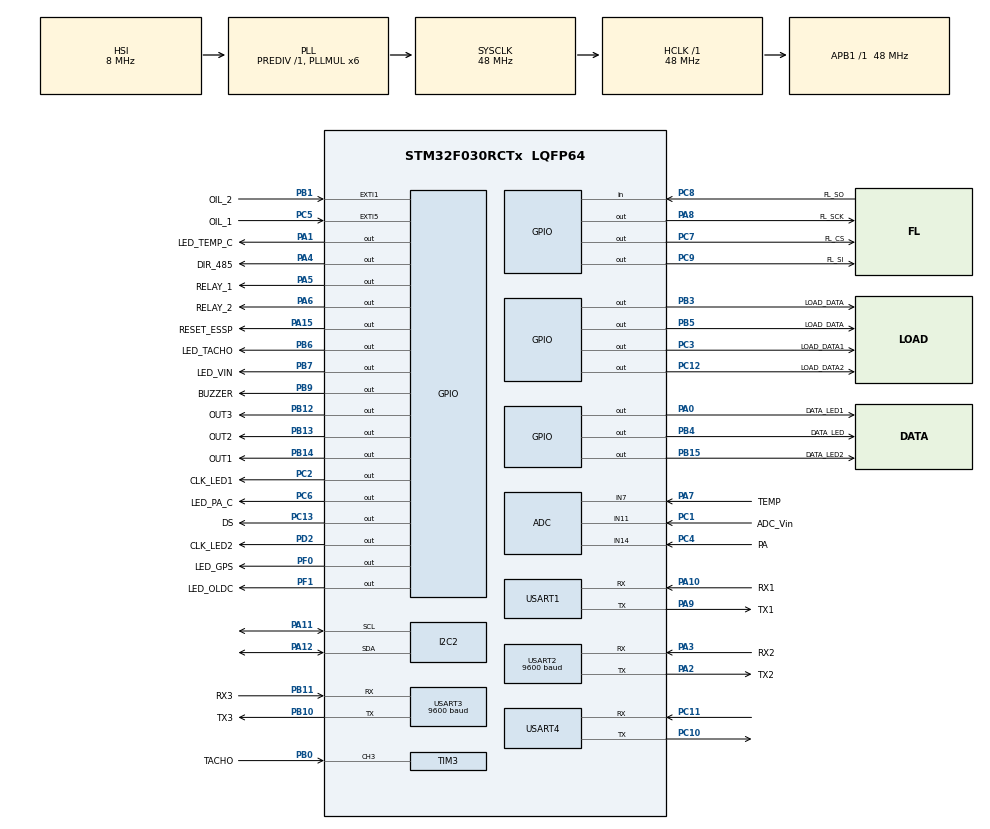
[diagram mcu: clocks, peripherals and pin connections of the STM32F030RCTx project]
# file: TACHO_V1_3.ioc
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I2C2.Timing=0x20303E5D
Mcu.Family=STM32F0
Mcu.Name=STM32F030RCTx
Mcu.Package=LQFP64
NVIC.ADC1_IRQn=true\:2\:0\:true\:false\:true\:true\:true\:true
NVIC.EXTI0_1_IRQn=true\:0\:0\:false\:false\:true\:true\:true\:true
NVIC.EXTI4_15_IRQn=true\:0\:0\:false\:false\:true\:true\:true\:true
NVIC.I2C2_IRQn=true\:2\:0\:true\:false\:true\:true\:true\:true
NVIC.TIM14_IRQn=true\:3\:0\:true\:false\:true\:true\:true\:true
NVIC.TIM1_BRK_UP_TRG_COM_IRQn=true\:3\:0\:true\:false\:true\:true\:true\:true
NVIC.TIM1_CC_IRQn=true\:3\:0\:true\:false\:true\:true\:true\:true
NVIC.TIM3_IRQn=true\:1\:0\:true\:false\:true\:true\:true\:true
NVIC.USART1_IRQn=true\:2\:0\:true\:false\:true\:true\:true\:true
NVIC.USART2_IRQn=true\:2\:0\:true\:false\:true\:true\:true\:true
NVIC.USART3_6_IRQn=true\:2\:0\:true\:false\:true\:true\:true\:true
PA0.GPIO_Label=DATA_LED1
PA0.Signal=GPIO_Output
PA1.GPIO_Label=LED_TEMP_C
PA1.Signal=GPIO_Output
PA10.GPIO_Label=RX1
PA10.Mode=Asynchronous
PA10.Signal=USART1_RX
PA11.Mode=I2C
PA11.Signal=I2C2_SCL
PA12.Mode=I2C
PA12.Signal=I2C2_SDA
PA13.Mode=Serial_Wire
PA13.Signal=SYS_SWDIO
PA14.Mode=Serial_Wire
PA14.Signal=SYS_SWCLK
PA15.GPIO_Label=RESET_ESSP
PA15.Signal=GPIO_Output
PA2.GPIO_Label=TX2
PA2.Mode=Asynchronous
PA2.Signal=USART2_TX
PA3.GPIO_Label=RX2
PA3.Mode=Asynchronous
PA3.Signal=USART2_RX
PA4.GPIO_Label=DIR_485
PA4.Signal=GPIO_Output
PA5.GPIO_Label=RELAY_1
PA5.Signal=GPIO_Output
PA6.GPIO_Label=RELAY_2
PA6.Signal=GPIO_Output
PA7.GPIO_Label=TEMP
PA7.Mode=IN7
PA7.Signal=ADC_IN7
PA8.GPIO_Label=FL_SCK
PA8.Signal=GPIO_Output
PA9.GPIO_Label=TX1
PA9.Mode=Asynchronous
PA9.Signal=USART1_TX
PB0.GPIO_Label=TACHO
PB0.Signal=S_TIM3_CH3
PB1.GPIO_Label=OIL_2
PB1.Signal=GPXTI1
PB10.GPIO_Label=TX3
PB10.Mode=Asynchronous
PB10.Signal=USART3_TX
PB11.GPIO_Label=RX3
PB11.Mode=Asynchronous
PB11.Signal=USART3_RX
PB12.GPIO_Label=OUT3
PB12.Signal=GPIO_Output
PB13.GPIO_Label=OUT2
PB13.Signal=GPIO_Output
PB14.GPIO_Label=OUT1
PB14.Signal=GPIO_Output
PB15.GPIO_Label=DATA_LED2
PB15.Signal=GPIO_Output
PB3.GPIO_Label=LOAD_DATA
PB3.Signal=GPIO_Output
PB4.GPIO_Label=DATA_LED
PB4.Signal=GPIO_Output
PB5.GPIO_Label=LOAD_DATA
PB5.Signal=GPIO_Output
PB6.GPIO_Label=LED_TACHO
PB6.Signal=GPIO_Output
PB7.GPIO_Label=LED_VIN
PB7.Signal=GPIO_Output
PB9.GPIO_Label=BUZZER
PB9.Signal=GPIO_Output
PC1.GPIO_Label=ADC_Vin
PC1.Mode=IN11
PC1.Signal=ADC_IN11
PC10.Mode=Asynchronous
PC10.Signal=USART4_TX
PC11.Mode=Asynchronous
PC11.Signal=USART4_RX
PC12.GPIO_Label=LOAD_DATA2
PC12.Signal=GPIO_Output
PC13.GPIO_Label=DS
PC13.Signal=GPIO_Output
PC14OSC32_IN.GPIO_Label=ST_CP
PC14OSC32_IN.Signal=GPIO_Output
PC15OSC32_OUT.GPIO_Label=SH_CP
PC15OSC32_OUT.Signal=GPIO_Output
PC2.GPIO_Label=CLK_LED1
PC2.Signal=GPIO_Output
PC3.GPIO_Label=LOAD_DATA1
PC3.Signal=GPIO_Output
PC4.GPIO_Label=PA
PC4.Mode=IN14
PC4.Signal=ADC_IN14
PC5.GPIO_Label=OIL_1
PC5.Signal=GPXTI5
PC6.GPIO_Label=LED_PA_C
PC6.Signal=GPIO_Output
PC7.GPIO_Label=FL_CS
PC7.Signal=GPIO_Output
PC8.GPIO_Label=FL_SO
PC8.Signal=GPIO_Input
PC9.GPIO_Label=FL_SI
PC9.Signal=GPIO_Output
PD2.GPIO_Label=CLK_LED2
PD2.Signal=GPIO_Output
PF0-OSC_IN.GPIO_Label=LED_GPS
PF0-OSC_IN.Signal=GPIO_Output
PF1-OSC_OUT.GPIO_Label=LED_OLDC
PF1-OSC_OUT.Signal=GPIO_Output
ProjectManager.HeapSize=0x200
ProjectManager.StackSize=0x400
ProjectManager.TargetToolchain=STM32CubeIDE
RCC.AHBFreq_Value=48000000
RCC.APB1Freq_Value=48000000
RCC.APB1TimFreq_Value=48000000
RCC.HCLKFreq_Value=48000000
RCC.PLLMUL=RCC_PLL_MUL6
RCC.SYSCLKFreq_VALUE=48000000
RCC.SYSCLKSource=RCC_SYSCLKSOURCE_PLLCLK
SH.S_TIM3_CH3.0=TIM3_CH3,Input_Capture3_from_TI3
TIM3.Channel-Input_Capture3_from_TI3=TIM_CHANNEL_3
USART1.VirtualMode-Asynchronous=VM_ASYNC
USART2.BaudRate=9600
USART2.VirtualMode-Asynchronous=VM_ASYNC
USART3.BaudRate=9600
USART3.VirtualMode-Asynchronous=VM_ASYNC
USART4.VirtualMode-Asynchronous=VM_ASYNC
VP_TIM14_VS_ClockSourceINT.Mode=Enable_Timer
VP_TIM16_VS_ClockSourceINT.Mode=Enable_Timer
VP_TIM17_VS_ClockSourceINT.Mode=Enable_Timer
VP_TIM1_VS_ClockSourceITR.Mode=TriggerSource_ITR1
VP_TIM3_VS_ClockSourceINT.Mode=Internal
VP_TIM3_VS_ClockSourceITR.Mode=TriggerSource_ITR1
VP_TIM6_VS_ClockSourceINT.Mode=Enable_Timer
VP_TIM7_VS_ClockSourceINT.Mode=Enable_Timer
board=custom

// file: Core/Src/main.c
/* USER CODE BEGIN Header */
/**
  ******************************************************************************
  * @file           : main.c
  * @brief          : Main program body
  ******************************************************************************
  * @attention
  *
  * Copyright (c) 2026 STMicroelectronics.
  * All rights reserved.
  *
  * This software is licensed under terms that can be found in the LICENSE file
  * in the root directory of this software component.
  * If no LICENSE file comes with this software, it is provided AS-IS.
  *
  ******************************************************************************
  */
/* USER CODE END Header */
#include "main.h"
#include "adc.h"
#include "i2c.h"
#include "tim.h"
#include "usart.h"
#include "gpio.h"

/* USER CODE BEGIN Includes */
#include "scheduler.h"
#include "app.h"
/* USER CODE END Includes */

void SystemClock_Config(void);

int main(void)
{

  /* MCU Configuration--------------------------------------------------------*/

  /* Reset of all peripherals, Initializes the Flash interface and the Systick. */
  HAL_Init();

  /* Configure the system clock */
  SystemClock_Config();

  /* Initialize all configured peripherals */
  MX_GPIO_Init();
  MX_ADC_Init();
  MX_I2C2_Init();
  MX_TIM1_Init();
  MX_TIM3_Init();
  MX_TIM14_Init();
  MX_USART1_UART_Init();
  MX_USART2_UART_Init();
  MX_USART3_UART_Init();
  MX_USART4_UART_Init();
  MX_TIM6_Init();
  MX_TIM7_Init();
  MX_TIM16_Init();
  MX_TIM17_Init();
  /* USER CODE BEGIN 2 */
  Scheduler_Init();

  /* USER CODE END 2 */

  /* Infinite loop */
  while (1)
  {

    /* USER CODE BEGIN 3 */
      Scheduler_Run();
  }
  /* USER CODE END 3 */
}

void SystemClock_Config(void)
{
  RCC_OscInitTypeDef RCC_OscInitStruct = {0};
  RCC_ClkInitTypeDef RCC_ClkInitStruct = {0};
  RCC_PeriphCLKInitTypeDef PeriphClkInit = {0};

  /** Initializes the RCC Oscillators according to the specified parameters
  * in the RCC_OscInitTypeDef structure.
  */
  RCC_OscInitStruct.OscillatorType = RCC_OSCILLATORTYPE_HSI|RCC_OSCILLATORTYPE_HSI14;
  RCC_OscInitStruct.HSIState = RCC_HSI_ON;
  RCC_OscInitStruct.HSI14State = RCC_HSI14_ON;
  RCC_OscInitStruct.HSICalibrationValue = RCC_HSICALIBRATION_DEFAULT;
  RCC_OscInitStruct.HSI14CalibrationValue = 16;
  RCC_OscInitStruct.PLL.PLLState = RCC_PLL_ON;
  RCC_OscInitStruct.PLL.PLLSource = RCC_PLLSOURCE_HSI;
  RCC_OscInitStruct.PLL.PLLMUL = RCC_PLL_MUL6;
  RCC_OscInitStruct.PLL.PREDIV = RCC_PREDIV_DIV1;
  if (HAL_RCC_OscConfig(&RCC_OscInitStruct) != HAL_OK)
  {
    Error_Handler();
  }

  /** Initializes the CPU, AHB and APB buses clocks
  */
  RCC_ClkInitStruct.ClockType = RCC_CLOCKTYPE_HCLK|RCC_CLOCKTYPE_SYSCLK
                              |RCC_CLOCKTYPE_PCLK1;
  RCC_ClkInitStruct.SYSCLKSource = RCC_SYSCLKSOURCE_PLLCLK;
  RCC_ClkInitStruct.AHBCLKDivider = RCC_SYSCLK_DIV1;
  RCC_ClkInitStruct.APB1CLKDivider = RCC_HCLK_DIV1;

  if (HAL_RCC_ClockConfig(&RCC_ClkInitStruct, FLASH_LATENCY_1) != HAL_OK)
  {
    Error_Handler();
  }
  PeriphClkInit.PeriphClockSelection = RCC_PERIPHCLK_USART1;
  PeriphClkInit.Usart1ClockSelection = RCC_USART1CLKSOURCE_PCLK1;
  if (HAL_RCCEx_PeriphCLKConfig(&PeriphClkInit) != HAL_OK)
  {
    Error_Handler();
  }
}

void Error_Handler(void)
{
  __disable_irq();
  while (1)
  {
  }
}
